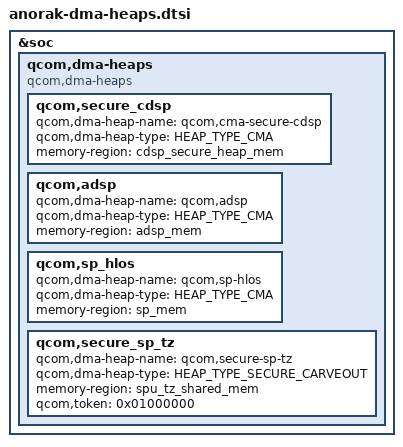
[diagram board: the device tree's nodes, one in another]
#include <dt-bindings/arm/msm/qcom_dma_heap_dt_constants.h>

&soc {
	qcom,dma-heaps {
		compatible = "qcom,dma-heaps";

		qcom,secure_cdsp {
			qcom,dma-heap-name = "qcom,cma-secure-cdsp";
			qcom,dma-heap-type = <HEAP_TYPE_CMA>;
			memory-region = <&cdsp_secure_heap_mem>;
		};

		qcom,adsp {
			qcom,dma-heap-name = "qcom,adsp";
			qcom,dma-heap-type = <HEAP_TYPE_CMA>;
			memory-region = <&adsp_mem>;
		};

		qcom,sp_hlos {
			qcom,dma-heap-name = "qcom,sp-hlos";
			qcom,dma-heap-type = <HEAP_TYPE_CMA>;
			memory-region = <&sp_mem>;
		};

		qcom,secure_sp_tz {
			qcom,dma-heap-name = "qcom,secure-sp-tz";
			qcom,dma-heap-type = <HEAP_TYPE_SECURE_CARVEOUT>;
			memory-region = <&spu_tz_shared_mem>;
			qcom,token = <0x01000000>;
		};
	};
};
